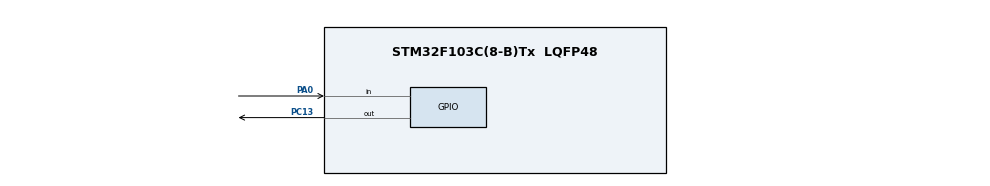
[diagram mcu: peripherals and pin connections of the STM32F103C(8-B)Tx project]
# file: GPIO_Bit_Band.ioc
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Mcu.Family=STM32F1
RCC.APB2Freq_Value=8000000
PA14.Mode=Serial_Wire
PC13-TAMPER-RTC.Signal=GPIO_Output
PA13.Mode=Serial_Wire
Mcu.Name=STM32F103C(8-B)Tx
Mcu.Package=LQFP48
ProjectManager.StackSize=0x400
PA0-WKUP.Signal=GPIO_Input
PA13.Signal=SYS_JTMS-SWDIO
PA14.Signal=SYS_JTCK-SWCLK
ProjectManager.HeapSize=0x200
ProjectManager.TargetToolchain=MDK-ARM V5
NVIC.PriorityGroup=NVIC_PRIORITYGROUP_4
PA0-WKUP.GPIO_PuPd=GPIO_PULLUP
RCC.APB1Freq_Value=8000000
board=custom

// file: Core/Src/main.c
/* USER CODE BEGIN Header */
/**
  ******************************************************************************
  * @file           : main.c
  * @brief          : Main program body
  ******************************************************************************
  * @attention
  *
  * <h2><center>&copy; Copyright (c) 2021 STMicroelectronics.
  * All rights reserved.</center></h2>
  *
  * This software component is licensed by ST under BSD 3-Clause license,
  * the "License"; You may not use this file except in compliance with the
  * License. You may obtain a copy of the License at:
  *                        opensource.org/licenses/BSD-3-Clause
  *
  ******************************************************************************
  */
/* USER CODE END Header */
#include "main.h"
#define PC13_OUT (*(volatile uint32_t *)0x422201B4)
#define PA0_IN (*(volatile uint32_t *)0x42210100)

/* USER CODE BEGIN PV */
uint32_t PC13_Bit_Band_Add;
uint32_t PC_ODR_Offset;
uint8_t pin_num1 = 13;

uint32_t PA0_Bit_Band_Add;
uint32_t PA_IDR_Offset;
uint8_t pin_num2 = 0;
uint8_t button_val;
/* USER CODE END PV */

void SystemClock_Config(void);
static void MX_GPIO_Init(void);

int main(void)
{

  /* MCU Configuration--------------------------------------------------------*/

  /* Reset of all peripherals, Initializes the Flash interface and the Systick. */
  HAL_Init();

  /* Configure the system clock */
  SystemClock_Config();

  /* Initialize all configured peripherals */
  MX_GPIO_Init();
  /* USER CODE BEGIN 2 */
	PC13_Bit_Band_Add = PERIPH_BB_BASE +(uint32_t)(&GPIOC->ODR)*32 + pin_num1*4;
	PC_ODR_Offset = (uint32_t)(&GPIOC->ODR);

	PA0_Bit_Band_Add = PERIPH_BB_BASE +(uint32_t)(&GPIOA->IDR)*32 + pin_num2*4;
	PA_IDR_Offset = (uint32_t)(&GPIOA->IDR);
  /* USER CODE END 2 */

  /* Infinite loop */
  while (1)
  {

    /* USER CODE BEGIN 3 */
		button_val = PA0_IN;
		PC13_OUT = button_val;
  }
  /* USER CODE END 3 */
}

void SystemClock_Config(void)
{
  RCC_OscInitTypeDef RCC_OscInitStruct = {0};
  RCC_ClkInitTypeDef RCC_ClkInitStruct = {0};

  /** Initializes the RCC Oscillators according to the specified parameters
  * in the RCC_OscInitTypeDef structure.
  */
  RCC_OscInitStruct.OscillatorType = RCC_OSCILLATORTYPE_HSI;
  RCC_OscInitStruct.HSIState = RCC_HSI_ON;
  RCC_OscInitStruct.HSICalibrationValue = RCC_HSICALIBRATION_DEFAULT;
  RCC_OscInitStruct.PLL.PLLState = RCC_PLL_NONE;
  if (HAL_RCC_OscConfig(&RCC_OscInitStruct) != HAL_OK)
  {
    Error_Handler();
  }
  /** Initializes the CPU, AHB and APB buses clocks
  */
  RCC_ClkInitStruct.ClockType = RCC_CLOCKTYPE_HCLK|RCC_CLOCKTYPE_SYSCLK
                              |RCC_CLOCKTYPE_PCLK1|RCC_CLOCKTYPE_PCLK2;
  RCC_ClkInitStruct.SYSCLKSource = RCC_SYSCLKSOURCE_HSI;
  RCC_ClkInitStruct.AHBCLKDivider = RCC_SYSCLK_DIV1;
  RCC_ClkInitStruct.APB1CLKDivider = RCC_HCLK_DIV1;
  RCC_ClkInitStruct.APB2CLKDivider = RCC_HCLK_DIV1;

  if (HAL_RCC_ClockConfig(&RCC_ClkInitStruct, FLASH_LATENCY_0) != HAL_OK)
  {
    Error_Handler();
  }
}

static void MX_GPIO_Init(void)
{
  GPIO_InitTypeDef GPIO_InitStruct = {0};

  /* GPIO Ports Clock Enable */
  __HAL_RCC_GPIOC_CLK_ENABLE();
  __HAL_RCC_GPIOA_CLK_ENABLE();

  /*Configure GPIO pin Output Level */
  HAL_GPIO_WritePin(GPIOC, GPIO_PIN_13, GPIO_PIN_RESET);

  /*Configure GPIO pin : PC13 */
  GPIO_InitStruct.Pin = GPIO_PIN_13;
  GPIO_InitStruct.Mode = GPIO_MODE_OUTPUT_PP;
  GPIO_InitStruct.Pull = GPIO_NOPULL;
  GPIO_InitStruct.Speed = GPIO_SPEED_FREQ_LOW;
  HAL_GPIO_Init(GPIOC, &GPIO_InitStruct);

  /*Configure GPIO pin : PA0 */
  GPIO_InitStruct.Pin = GPIO_PIN_0;
  GPIO_InitStruct.Mode = GPIO_MODE_INPUT;
  GPIO_InitStruct.Pull = GPIO_PULLUP;
  HAL_GPIO_Init(GPIOA, &GPIO_InitStruct);

}

void Error_Handler(void)
{
}

/************************ (C) COPYRIGHT STMicroelectronics *****END OF FILE****/
